AUTOSAR XML (schema 4-0-3)
package /ComponentTypes
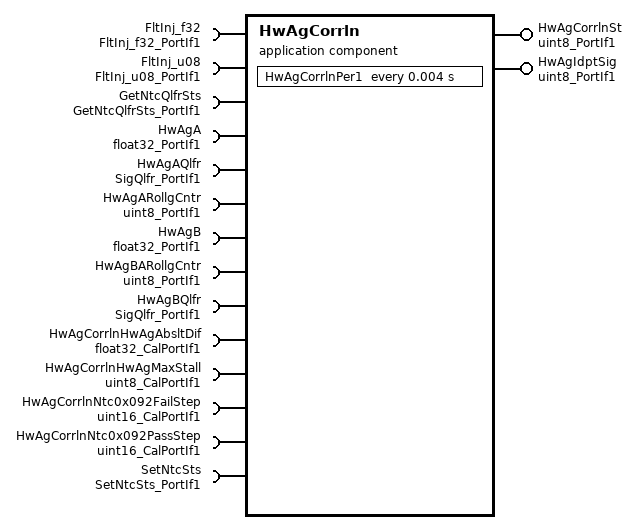
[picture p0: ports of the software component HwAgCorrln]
  application sw component type HwAgCorrln
    provide port HwAgCorrlnSt: nonqueued-sender-com-spec{data-element=Val, init-value=3}, provided-interface=uint8_PortIf1
    provide port HwAgIdptSig: nonqueued-sender-com-spec{data-element=Val, init-value=2}, provided-interface=uint8_PortIf1
    14 x require port:
      FltInj_f32: required-interface=FltInj_f32_PortIf1
      FltInj_u08: required-interface=FltInj_u08_PortIf1
      GetNtcQlfrSts: required-interface=GetNtcQlfrSts_PortIf1
      HwAgA: nonqueued-receiver-com-spec{data-element=Val, filter=data-filter-type=ALWAYS, init-value=0}, required-interface=float32_PortIf1
      HwAgAQlfr: nonqueued-receiver-com-spec{data-element=Val, filter=data-filter-type=ALWAYS, init-value=0}, required-interface=SigQlfr_PortIf1
      HwAgARollgCntr: nonqueued-receiver-com-spec{data-element=Val, filter=data-filter-type=ALWAYS, init-value=0}, required-interface=uint8_PortIf1
      HwAgB: nonqueued-receiver-com-spec{data-element=Val, filter=data-filter-type=ALWAYS, init-value=0}, required-interface=float32_PortIf1
      HwAgBARollgCntr: nonqueued-receiver-com-spec{data-element=Val, filter=data-filter-type=ALWAYS, init-value=0}, required-interface=uint8_PortIf1
      HwAgBQlfr: nonqueued-receiver-com-spec{data-element=Val, filter=data-filter-type=ALWAYS, init-value=0}, required-interface=SigQlfr_PortIf1
      HwAgCorrlnHwAgAbsltDif: parameter-require-com-spec{init-value=15, parameter=Val}, required-interface=float32_CalPortIf1
      HwAgCorrlnHwAgMaxStall: parameter-require-com-spec{init-value=25, parameter=Val}, required-interface=uint8_CalPortIf1
      HwAgCorrlnNtc0x092FailStep: parameter-require-com-spec{init-value=400, parameter=Val}, required-interface=uint16_CalPortIf1
      HwAgCorrlnNtc0x092PassStep: parameter-require-com-spec{init-value=4000, parameter=Val}, required-interface=uint16_CalPortIf1
      SetNtcSts: required-interface=SetNtcSts_PortIf1
    behavior HwAgCorrln_InternalBehavior
      ar-typed-per-instance-memorys:
        6 x data, all with sw-calibration-access=READ-ONLY:
          dHwAgCorrlnAgAAvl: type=boolean
          dHwAgCorrlnAgBAvl: type=boolean
          HwAgARollgCntPrev: type=uint8
          HwAgAStallCntPrev: type=uint8
          HwAgBRollgCntPrev: type=uint8
          HwAgBStallCntPrev: type=uint8
      timing event TMT_HwAgCorrlnPer1: start-on-event=HwAgCorrlnPer1, period=0.004
      runnable HwAgCorrlnPer1
        data-receive-point-by-arguments:
          6 x access:
            REC_HwAgA_Val: accessed-variable=HwAgA.Val
            REC_HwAgAQlfr_Val: accessed-variable=HwAgAQlfr.Val
            REC_HwAgARollgCntr_Val: accessed-variable=HwAgARollgCntr.Val
            REC_HwAgB_Val: accessed-variable=HwAgB.Val
            REC_HwAgBARollgCntr_Val: accessed-variable=HwAgBARollgCntr.Val
            REC_HwAgBQlfr_Val: accessed-variable=HwAgBQlfr.Val
        data-send-points:
          access SEND_HwAgCorrlnSt_Val: accessed-variable=HwAgCorrlnSt.Val
          access SEND_HwAgIdptSig_Val: accessed-variable=HwAgIdptSig.Val
        4 x sync call, all with timeout=0:
          SC_FltInj_f32_Oper: operation=FltInj_f32.Oper
          SC_FltInj_u08_Oper: operation=FltInj_u08.Oper
          SC_GetNtcQlfrSts_Oper: operation=GetNtcQlfrSts.Oper
          SC_SetNtcSts_Oper: operation=SetNtcSts.Oper
  swc implementation HwAgCorrln_Implementation: behavior=HwAgCorrln_InternalBehavior
    code-descriptors:
      code Default: artifact-descriptors=autosar-engineering-object={short-label=Default, category=SWSRC}
